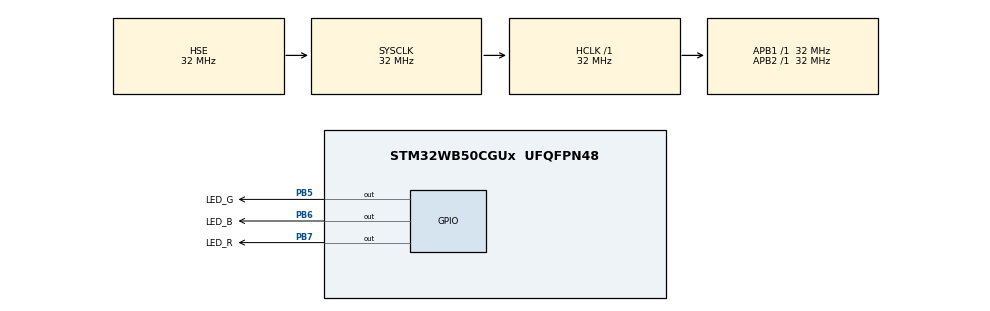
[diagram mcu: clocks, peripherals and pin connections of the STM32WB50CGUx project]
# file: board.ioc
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Mcu.Family=STM32WB
Mcu.Name=STM32WB50CGUx
Mcu.Package=UFQFPN48
NVIC.HSEM_IRQn=true\:0\:0\:false\:false\:true\:false\:true\:true
NVIC.IPCC_C1_RX_IRQn=true\:0\:0\:false\:false\:true\:true\:true\:true
NVIC.IPCC_C1_TX_IRQn=true\:0\:0\:false\:false\:true\:true\:true\:true
NVIC.PriorityGroup=NVIC_PRIORITYGROUP_4
OSC_IN.Mode=HSE-External-Oscillator
OSC_IN.Signal=RCC_OSC_IN
OSC_OUT.Mode=HSE-External-Oscillator
OSC_OUT.Signal=RCC_OSC_OUT
PA13.Mode=Serial_Wire
PA13.Signal=SYS_JTMS-SWDIO
PA14.Mode=Serial_Wire
PA14.Signal=SYS_JTCK-SWCLK
PA9.Signal=USART1_TX
PB5.GPIO_Label=LED_G
PB5.GPIO_ModeDefaultOutputPP=GPIO_MODE_OUTPUT_OD
PB5.GPIO_PuPd=GPIO_NOPULL
PB5.GPIO_Speed=GPIO_SPEED_FREQ_LOW
PB5.Signal=GPIO_Output
PB6.GPIO_Label=LED_B
PB6.GPIO_ModeDefaultOutputPP=GPIO_MODE_OUTPUT_OD
PB6.GPIO_PuPd=GPIO_NOPULL
PB6.Signal=GPIO_Output
PB7.GPIO_Label=LED_R
PB7.GPIO_ModeDefaultOutputPP=GPIO_MODE_OUTPUT_OD
PB7.GPIO_PuPd=GPIO_NOPULL
PB7.Signal=GPIO_Output
PC14-OSC32_IN.Mode=LSE-External-Oscillator
PC14-OSC32_IN.Signal=RCC_OSC32_IN
PC15-OSC32_OUT.Mode=LSE-External-Oscillator
PC15-OSC32_OUT.Signal=RCC_OSC32_OUT
ProjectManager.HeapSize=0x400
ProjectManager.StackSize=0x1000
ProjectManager.TargetToolchain=Makefile
RCC.ADCFreq_Value=32000000
RCC.AHBFreq_Value=32000000
RCC.APB1Freq_Value=32000000
RCC.APB1TimFreq_Value=32000000
RCC.APB2Freq_Value=32000000
RCC.APB2TimFreq_Value=32000000
RCC.APB3Freq_Value=16000000
RCC.CortexFreq_Value=32000000
RCC.HCLKFreq_Value=32000000
RCC.HSE_VALUE=32000000
RCC.HSI48_VALUE=48000000
RCC.HSI_VALUE=16000000
RCC.PLLSourceVirtual=RCC_PLLSOURCE_HSE
RCC.RFWKPClockSelection=RCC_RFWKPCLKSOURCE_LSE
RCC.RTCClockSelection=RCC_RTCCLKSOURCE_LSE
RCC.SYSCLKFreq_VALUE=32000000
RCC.SYSCLKSource=RCC_SYSCLKSOURCE_HSE
RCC.VCOOutputFreq_Value=256000000
VP_HSEM_VS_HSEM.Mode=HSEM_Activate
VP_IPCC_VS_IPCC.Mode=IPCC_Activate
VP_MEMORYMAP_VS_MEMORYMAP.Mode=CurAppReg
VP_RTC_VS_RTC_Activate.Mode=RTC_Enabled
board=custom

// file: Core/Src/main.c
/* USER CODE BEGIN Header */
/**
  ******************************************************************************
  * @file           : main.c
  * @brief          : Main program body
  ******************************************************************************
  * @attention
  *
  * Copyright (c) 2024 STMicroelectronics.
  * All rights reserved.
  *
  * This software is licensed under terms that can be found in the LICENSE file
  * in the root directory of this software component.
  * If no LICENSE file comes with this software, it is provided AS-IS.
  *
  ******************************************************************************
  */
/* USER CODE END Header */
#include "main.h"
#include "ipcc.h"
#include "rtc.h"
#include "gpio.h"

void SystemClock_Config(void);

/* USER CODE BEGIN 0 */
extern void zig_entrypoint(void);
/* USER CODE END 0 */

int main(void)
{

  /* MCU Configuration--------------------------------------------------------*/

  /* Reset of all peripherals, Initializes the Flash interface and the Systick. */
  HAL_Init();

  /* Configure the system clock */
  SystemClock_Config();

  /* IPCC initialisation */
  MX_IPCC_Init();

  /* Initialize all configured peripherals */
  MX_GPIO_Init();
  MX_RTC_Init();

  /* Infinite loop */
  /* USER CODE BEGIN WHILE */
  zig_entrypoint();

  while (1)
  {
    /* USER CODE END WHILE */

  }
}

void SystemClock_Config(void)
{
  RCC_OscInitTypeDef RCC_OscInitStruct = {0};
  RCC_ClkInitTypeDef RCC_ClkInitStruct = {0};

  /** Configure LSE Drive Capability
  */
  HAL_PWR_EnableBkUpAccess();
  __HAL_RCC_LSEDRIVE_CONFIG(RCC_LSEDRIVE_MEDIUMHIGH);

  /** Initializes the RCC Oscillators according to the specified parameters
  * in the RCC_OscInitTypeDef structure.
  */
  RCC_OscInitStruct.OscillatorType = RCC_OSCILLATORTYPE_HSI|RCC_OSCILLATORTYPE_HSE
                              |RCC_OSCILLATORTYPE_LSE;
  RCC_OscInitStruct.HSEState = RCC_HSE_ON;
  RCC_OscInitStruct.LSEState = RCC_LSE_ON;
  RCC_OscInitStruct.HSIState = RCC_HSI_ON;
  RCC_OscInitStruct.HSICalibrationValue = RCC_HSICALIBRATION_DEFAULT;
  RCC_OscInitStruct.PLL.PLLState = RCC_PLL_NONE;
  if (HAL_RCC_OscConfig(&RCC_OscInitStruct) != HAL_OK)
  {
    Error_Handler();
  }

  /** Configure the SYSCLKSource, HCLK, PCLK1 and PCLK2 clocks dividers
  */
  RCC_ClkInitStruct.ClockType = RCC_CLOCKTYPE_HCLK4|RCC_CLOCKTYPE_HCLK2
                              |RCC_CLOCKTYPE_HCLK|RCC_CLOCKTYPE_SYSCLK
                              |RCC_CLOCKTYPE_PCLK1|RCC_CLOCKTYPE_PCLK2;
  RCC_ClkInitStruct.SYSCLKSource = RCC_SYSCLKSOURCE_HSE;
  RCC_ClkInitStruct.AHBCLKDivider = RCC_SYSCLK_DIV1;
  RCC_ClkInitStruct.APB1CLKDivider = RCC_HCLK_DIV1;
  RCC_ClkInitStruct.APB2CLKDivider = RCC_HCLK_DIV1;
  RCC_ClkInitStruct.AHBCLK2Divider = RCC_SYSCLK_DIV1;
  RCC_ClkInitStruct.AHBCLK4Divider = RCC_SYSCLK_DIV1;

  if (HAL_RCC_ClockConfig(&RCC_ClkInitStruct, FLASH_LATENCY_1) != HAL_OK)
  {
    Error_Handler();
  }
}

void Error_Handler(void)
{
  __disable_irq();
  while (1)
  {
  }
}
